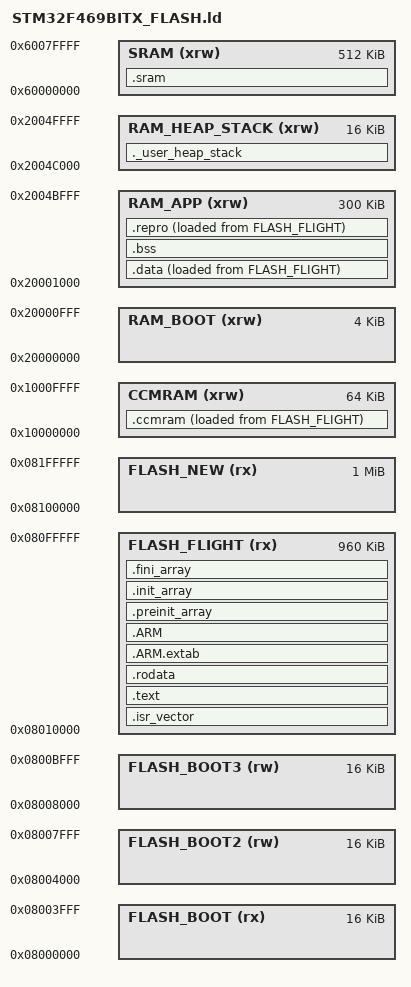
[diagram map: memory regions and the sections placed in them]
/*
******************************************************************************
**
** @file        : LinkerScript.ld
**
** @author      : Auto-generated by STM32CubeIDE
**
** @brief       : Linker script for STM32F469BITx Device from STM32F4 series
**                      2048Kbytes FLASH
**                      64Kbytes CCMRAM
**                      320Kbytes RAM
**
**                Set heap size, stack size and stack location according
**                to application requirements.
**
**                Set memory bank area and size if external memory is used
**
**  Target      : STMicroelectronics STM32
**
**  Distribution: The file is distributed as is, without any warranty
**                of any kind.
**
******************************************************************************
** @attention
**
** Copyright (c) 2023 STMicroelectronics.
** All rights reserved.
**
** This software is licensed under terms that can be found in the LICENSE file
** in the root directory of this software component.
** If no LICENSE file comes with this software, it is provided AS-IS.
**
******************************************************************************
*/

/* Entry Point */
ENTRY(Reset_Handler)

/* Highest address of the user mode stack */
_estack = 0x20050000; /* end of "RAM" Ram type memory */

_Min_Heap_Size = 0x300; /* required amount of heap */
_Min_Stack_Size = 0x400; /* required amount of stack */

/* Memories definition */
MEMORY
{
  RAM_BOOT (xrw)      : ORIGIN = 0x20000000, LENGTH = 4K
  RAM_APP (xrw)       : ORIGIN = 0x20001000, LENGTH = 300K
  RAM_HEAP_STACK (xrw): ORIGIN = 0x2004C000, LENGTH = 16K
  CCMRAM (xrw)        : ORIGIN = 0x10000000, LENGTH = 64K
  FLASH_BOOT (rx)     : ORIGIN = 0x8000000,  LENGTH = 16K	  /*	Section 0    	*/
  FLASH_BOOT2 (rw)    : ORIGIN = 0x8004000,  LENGTH = 16K	  /*	Section 1    	*/
  FLASH_BOOT3 (rw)    : ORIGIN = 0x8008000,  LENGTH = 16K	  /*	Section 2    	*/
  FLASH_FLIGHT (rx)   : ORIGIN = 0x8010000,  LENGTH = 960K	  /*	Section 4 ~ 11	*/
  FLASH_NEW (rx)      : ORIGIN = 0x8100000,  LENGTH = 1024K   /*	Section 12 ~ 23	*/
  SRAM(xrw)		      : ORIGIN = 0x60000000, LENGTH = 512K
}
  _sflash_new = ORIGIN(FLASH_NEW);
  _sflash_flight = ORIGIN(FLASH_FLIGHT);
  _sdata_boot = ORIGIN(RAM_BOOT);
/* Sections */
SECTIONS
{
  /* The startup code into "FLASH" Rom type memory */
  .isr_vector :
  {
    . = ALIGN(4);
    KEEP(*(.isr_vector)) /* Startup code */
    . = ALIGN(4);
  } >FLASH_FLIGHT

  /* The program code and other data into "FLASH" Rom type memory */
  .text :
  {
    . = ALIGN(4);
    *(EXCLUDE_FILE(./src/src_user/ReProgramming/*).text)           /* .text sections (code) */
    *(EXCLUDE_FILE(./src/src_user/ReProgramming/*).text*)          /* .text* sections (code) */
    *(EXCLUDE_FILE(./src/src_user/ReProgramming/*).glue_7)         /* glue arm to thumb code */
    *(EXCLUDE_FILE(./src/src_user/ReProgramming/*).glue_7t)        /* glue thumb to arm code */
    *(EXCLUDE_FILE(./src/src_user/ReProgramming/*).eh_frame)

    KEEP (*(EXCLUDE_FILE(./src/src_user/ReProgramming/*).init))
    KEEP (*(EXCLUDE_FILE(./src/src_user/ReProgramming/*).fini))

    . = ALIGN(4);
    _etext = .;        /* define a global symbols at end of code */
  } >FLASH_FLIGHT

  /* Constant data into "FLASH" Rom type memory */
  .rodata :
  {
    . = ALIGN(4);
    *(EXCLUDE_FILE(./src/src_user/ReProgramming/*).rodata)         /* .rodata sections (constants, strings, etc.) */
    *(EXCLUDE_FILE(./src/src_user/ReProgramming/*).rodata*)        /* .rodata* sections (constants, strings, etc.) */
    . = ALIGN(4);
  } >FLASH_FLIGHT

  .ARM.extab   : {
    . = ALIGN(4);
    *(.ARM.extab* .gnu.linkonce.armextab.*)
    . = ALIGN(4);
  } >FLASH_FLIGHT

  .ARM : {
    . = ALIGN(4);
    __exidx_start = .;
    *(.ARM.exidx*)
    __exidx_end = .;
    . = ALIGN(4);
  } >FLASH_FLIGHT

  .preinit_array     :
  {
    . = ALIGN(4);
    PROVIDE_HIDDEN (__preinit_array_start = .);
    KEEP (*(EXCLUDE_FILE(./src/src_user/ReProgramming/*).preinit_array*))
    PROVIDE_HIDDEN (__preinit_array_end = .);
    . = ALIGN(4);
  } >FLASH_FLIGHT

  .init_array :
  {
    . = ALIGN(4);
    PROVIDE_HIDDEN (__init_array_start = .);
    KEEP (*(SORT(EXCLUDE_FILE(./src/src_user/ReProgramming/*).init_array.*)))
    KEEP (*(EXCLUDE_FILE(./src/src_user/ReProgramming/*).init_array*))
    PROVIDE_HIDDEN (__init_array_end = .);
    . = ALIGN(4);
  } >FLASH_FLIGHT

  .fini_array :
  {
    . = ALIGN(4);
    PROVIDE_HIDDEN (__fini_array_start = .);
    KEEP (*(SORT(EXCLUDE_FILE(./src/src_user/ReProgramming/*).fini_array.*)))
    KEEP (*(EXCLUDE_FILE(./src/src_user/ReProgramming/*).fini_array*))
    PROVIDE_HIDDEN (__fini_array_end = .);
    . = ALIGN(4);
  } >FLASH_FLIGHT

  /* Used by the startup to initialize data */
  _sidata = LOADADDR(.data);

  /* Initialized data sections into "RAM" Ram type memory */
  .data :
  {
    . = ALIGN(4);
    _sdata = .;        /* create a global symbol at data start */
    *(EXCLUDE_FILE(./src/src_user/ReProgramming/*).data)           /* .data sections */
    *(EXCLUDE_FILE(./src/src_user/ReProgramming/*).data*)          /* .data* sections */
    *(EXCLUDE_FILE(./src/src_user/ReProgramming/*).RamFunc)        /* .RamFunc sections */
    *(EXCLUDE_FILE(./src/src_user/ReProgramming/*).RamFunc*)       /* .RamFunc* sections */

    . = ALIGN(4);
    _edata = .;        /* define a global symbol at data end */

  } >RAM_APP AT> FLASH_FLIGHT

  _siccmram = LOADADDR(.ccmram);

  /* CCM-RAM section
  *
  * IMPORTANT NOTE!
  * If initialized variables will be placed in this section,
  * the startup code needs to be modified to copy the init-values.
  */
  .ccmram :
  {
    . = ALIGN(4);
    _sccmram = .;       /* create a global symbol at ccmram start */
    *(.ccmram)
    *(.ccmram*)

    . = ALIGN(4);
    _eccmram = .;       /* create a global symbol at ccmram end */
  } >CCMRAM AT> FLASH_FLIGHT

  /* Uninitialized data section into "RAM" Ram type memory */
  . = ALIGN(4);
  .bss :
  {
    /* This is used by the startup in order to initialize the .bss section */
    _sbss = .;         /* define a global symbol at bss start */
    __bss_start__ = _sbss;
    *(EXCLUDE_FILE(./src/src_user/ReProgramming/*).bss)
    *(EXCLUDE_FILE(./src/src_user/ReProgramming/*).bss*)
    *(EXCLUDE_FILE(./src/src_user/ReProgramming/*)COMMON)

    . = ALIGN(4);
    _ebss = .;         /* define a global symbol at bss end */
    __bss_end__ = _ebss;
  } >RAM_APP
  
  /* Memory Area for Reprogramming */
  _isrepro = LOADADDR(.repro);
  .repro :
  {
	. = ALIGN(4);
	_srepro = .;
    /*KEEP(./src/src_user/ReProgramming/Command/Cmd_repro_nop.o(.text* .rodata* .data* .bss* .COMMON*))*/

   	. = ALIGN(4); 
  } >RAM_APP AT> FLASH_FLIGHT

  /* User_heap_stack section, used to check that there is enough "RAM" Ram  type memory left */
  ._user_heap_stack :
  {
    . = ALIGN(8);
    PROVIDE ( end = . );
    PROVIDE ( _end = . );
    . = . + _Min_Heap_Size;
    . = . + _Min_Stack_Size;
    . = ALIGN(8);
  } >RAM_HEAP_STACK
  
  .sram :
  {
  _ssram = .;
   . = ALIGN(4);
   *(.sram)
   *(.sram*)
   _esram = .;
  } >SRAM

  /* Remove information from the compiler libraries */
  /DISCARD/ :
  {
    libc.a ( * )
    libm.a ( * )
    libgcc.a ( * )
  }

  .ARM.attributes 0 : { *(.ARM.attributes) }
}
